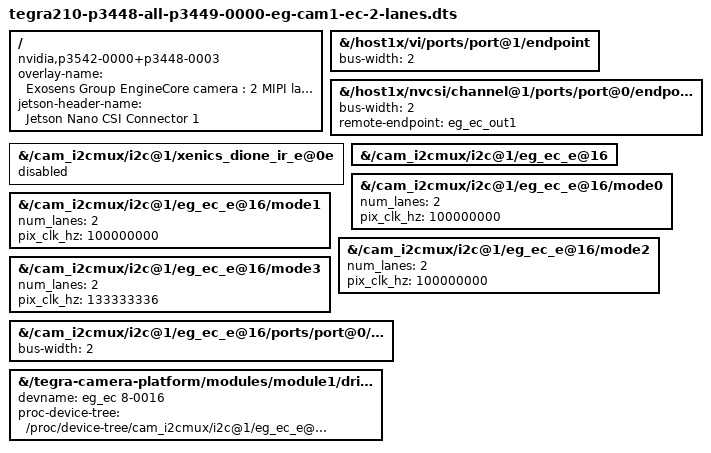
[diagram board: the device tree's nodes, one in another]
// SPDX-License-Identifier: GPL-2.0-only
/*
 * Jetson Device-tree overlay for Camera E3331 on t23x platforms
 *
 * Copyright (c) 2022 NVIDIA CORPORATION. All rights reserved.
 *
 */


/dts-v1/;
/plugin/;


/ {
	overlay-name = "Exosens Group EngineCore camera : 2 MIPI lane";
	jetson-header-name = "Jetson Nano CSI Connector 1";
	compatible = "nvidia,p3542-0000+p3448-0003", "nvidia,p3449-0000-a02+p3448-0000-a02","nvidia,p3449-0000-a01+p3448-0000-a01", "nvidia,p3449-0000-b00+p3448-0000-b00", "nvidia,p3449-0000-b00+p3448-0002-b00";

	fragment@0 {
		target-path = "/host1x/vi/ports/port@1/endpoint";
		__overlay__ {
			bus-width=<2>;
		};
	};

	fragment@1 {
		target-path = "/host1x/nvcsi/channel@1/ports/port@0/endpoint@2";
		__overlay__ {
			bus-width=<2>;
         remote-endpoint = <&eg_ec_out1>;
		};
	};

   // Disable Dione cameras
	fragment@2 {
		target-path = "/cam_i2cmux/i2c@1/xenics_dione_ir_e@0e";
		__overlay__ {
         status = "disabled";
		};
	};

   // Enable EngineCore cameras
	fragment@3 {
		target-path = "/cam_i2cmux/i2c@1/eg_ec_e@16";
		__overlay__ {
         status = "okay";
		};
	};
	fragment@5 {
		target-path = "/cam_i2cmux/i2c@1/eg_ec_e@16/mode0";
		__overlay__ {
         num_lanes = "2";
         pix_clk_hz = "100000000";
		};
	};
	fragment@6 {
		target-path = "/cam_i2cmux/i2c@1/eg_ec_e@16/mode1";
		__overlay__ {
         num_lanes = "2";
         pix_clk_hz = "100000000";
		};
	};
	fragment@8 {
		target-path = "/cam_i2cmux/i2c@1/eg_ec_e@16/mode2";
		__overlay__ {
         num_lanes = "2";
         pix_clk_hz = "100000000";
		};
	};
	fragment@9 {
		target-path = "/cam_i2cmux/i2c@1/eg_ec_e@16/mode3";
		__overlay__ {
         num_lanes = "2";
         pix_clk_hz = "133333336";
		};
	};
	fragment@10 {
		target-path = "/cam_i2cmux/i2c@1/eg_ec_e@16/ports/port@0/endpoint";
		__overlay__ {
			bus-width=<2>;
		};
	};

	fragment@11 {
		target-path = "/tegra-camera-platform/modules/module1/drivernode0";
		__overlay__ {
         devname = "eg_ec 8-0016";
			proc-device-tree = "/proc/device-tree/cam_i2cmux/i2c@1/eg_ec_e@16";
		};
	};
};
